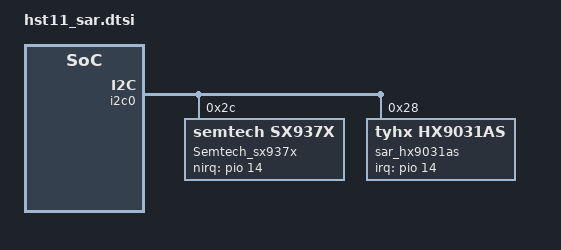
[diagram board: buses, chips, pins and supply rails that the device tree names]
/* Copyright (c) 2016, The Linux Foundation. All rights reserved.
 *
 * This program is free software; you can redistribute it and/or modify
 * it under the terms of the GNU General Public License version 2 and
 * only version 2 as published by the Free Software Foundation.
 *
 * This program is distributed in the hope that it will be useful,
 * but WITHOUT ANY WARRANTY; without even the implied warranty of
 * MERCHANTABILITY or FITNESS FOR A PARTICULAR PURPOSE.  See the
 * GNU General Public License for more details.
 */
/*Tab A11 code for AX7800A-650|AX7800A-744|AX7800A-746 by lichang at 20240515 start*/
/*Tab A11 code for AX7800A-1057 by zhawei at 20250527 start*/
/*Tab A11 code for AX7800A-2707|AX7800A-2299 by zhawei at 20250619 start*/
&i2c0{
    Semtech_sx937x@2c {
        compatible = "semtech,sx937x";
        reg = <0x2c>;
        status = "okay";
        Semtech,nirq-gpio = <&pio 14 0x00>;
        /*use PH3/4 as the reference sensor
        set it to 0xff if the ref-phases-x is not used*/
        semtech,main-phases = <0x0E>;
        semtech,ref-phases = <0x11>;
        semtech,fw-num = <250618>;
        Semtech,reg-init = <
        0x8024 0x00001F00
        0x4004 0x00000070
        0x4008 0x00000008
        0x8020 0x00000035
        0x8028 0x0000085E
        0x8034 0x0000085E
        0x8040 0x0000085E
        0x804C 0x0000085E
        0x8058 0x0000085E
        0x8064 0x0000085C
        0x8070 0x0000085C
        0x807C 0x0000085C
        0x8030 0x00FE492C
        0x803C 0x00FE4925
        0x8048 0x00FE4964
        0x8054 0x00FE5924
        0x8060 0x0002C924
        0x8098 0x000000FF
        0x80B8 0x00000015
        0x80D8 0x00000046
        0x80F8 0x00000020
        0x8118 0x000000FF
        0x80A0 0x00000000
        0x80C0 0x0A0700E2
        0x80E0 0x120D00E2
        0x8100 0x2A2800E2
        0x8188 0x08000000
        0x818C 0x08000004
        0x8090 0x00005000
        0x80B0 0x00005000
        0x80D0 0x02005000
        0x80F0 0x00005000
        0x8110 0x00005000
        0x8088 0x06300000
        0x80A8 0x00300000
        0x80C8 0x00300000
        0x80E8 0x00300000
        0x8108 0x06300000
        0x8128 0x00000000
        0x8148 0x00000000
        0x8168 0x00000000
        0x808C 0x60200000
        0x80AC 0x60201130
        0x80CC 0x60201630
        0x80EC 0x60201600
        0x810C 0x60200030
        0x812C 0x00000000
        0x814C 0x00000000
        0x816C 0x00000000
        0x8024 0x00001F1F>;
    };
    sar_hx9031as@28 {
       compatible = "tyhx,hx9031as";
       reg = <0x28>;
       tyhx,irq-gpio = <&pio 14 0x00>;
       tyhx,channel-flag = <0x1F>;
       tyhx,fw-num = <250619>;
       tyhx,reg-num = <82>;
       tyhx,reg-init = <
       0x24 0x00
       0x00 0x00
       0x23 0x00
       0x02 0x16
       0x0D 0x00
       0x0E 0x00
       0x0F 0x01
       0x10 0x6C
       0x11 0x34
       0x12 0x44
       0x13 0x24
       0x14 0x34
       0x1F 0x1F
       0x21 0x1F
       0x2A 0x33
       0x2B 0x33
       0x29 0x03
       0x2C 0x88
       0x2D 0x88
       0x2E 0x18
       0x2F 0x11
       0x30 0x11
       0x38 0xF0
       0x39 0xFF
       0x3A 0x3B
       0x3B 0x0A
       0x3C 0x21
       0x6C 0x01
       0x6D 0x01
       0x80 0x40
       0x81 0x00
       0x82 0x04
       0x83 0x00
       0x84 0x40
       0x85 0x00
       0x86 0x04
       0x87 0x00
       0x9E 0x06
       0x9F 0x00
       0x88 0x20
       0x89 0x00
       0x8A 0x03
       0x8B 0x00
       0x8C 0x20
       0x8D 0x00
       0x8E 0x03
       0x8F 0x00
       0xA2 0x05
       0xA3 0x00
       0xA8 0x00
       0xA9 0x00
       0xAA 0x00
       0xAB 0x00
       0xAC 0x00
       0xC0 0x00
       0xC1 0x00
       0xC4 0x00
       0xC5 0x00
       0xC7 0x00
       0xC8 0x47
       0xCA 0x00
       0x98 0x05
       0xA0 0x03
       0xA4 0x04
       0xA6 0x04
       0xAD 0x50
       0xAE 0x50
       0xAF 0x05
       0x93 0x4B
       0x94 0x70
       0x95 0x48
       0x96 0x3B
       0x03 0x30
       0x04 0x00
       0x05 0x2C
       0x06 0x00
       0x07 0x00
       0x08 0x03
       0x09 0x03
       0x0A 0x00
       0x0B 0xC0
       0x0C 0x02>;
    };
};
/*Tab A11 code for AX7800A-2707|AX7800A-2299 by zhawei at 20250619 end*/
/*Tab A11 code for AX7800A-1057 by zhawei at 20250527 end*/
/*Tab A11 code for AX7800A-650|AX7800A-744|AX7800A-746 by lichang at 20240515 end*/
